AUTOSAR XML (schema 3.1.2)
package /Components/SWC_PFilSlow
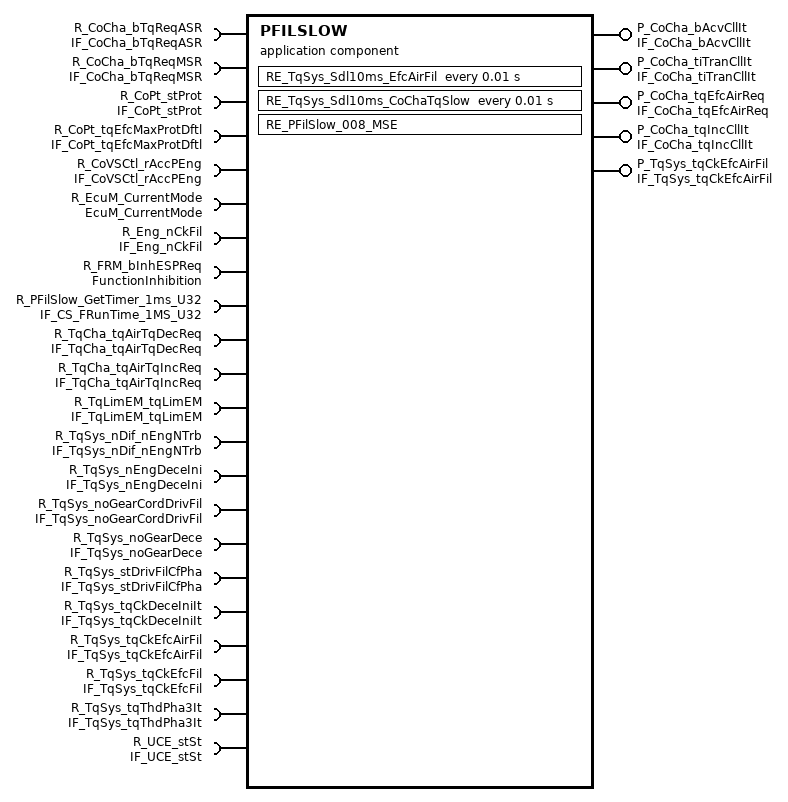
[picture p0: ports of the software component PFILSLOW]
  application software component type PFILSLOW  # PFilSlow
    5 x provide port:
      P_CoCha_bAcvCllIt: unqueued-sender-com-spec{data-element=CoCha_bAcvCllIt, can-invalidate=false, init-value=ConstantValue}, provided-interface=IF_CoCha_bAcvCllIt  # Requirement: 01552_10_01786-PFilSlow.I101(0)
      P_CoCha_tiTranCllIt: unqueued-sender-com-spec{data-element=CoCha_tiTranCllIt, can-invalidate=false, init-value=ConstantValue1}, provided-interface=IF_CoCha_tiTranCllIt  # Requirement: 01552_10_01786-PFilSlow.I102(0)
      P_CoCha_tqEfcAirReq: unqueued-sender-com-spec{data-element=CoCha_tqEfcAirReq, can-invalidate=false, init-value=ConstantValue3}, provided-interface=IF_CoCha_tqEfcAirReq  # Requirement: 01552_10_01786-PFilSlow.I100(0)
      P_CoCha_tqIncCllIt: unqueued-sender-com-spec{data-element=CoCha_tqIncCllIt, can-invalidate=false, init-value=ConstantValue5}, provided-interface=IF_CoCha_tqIncCllIt  # Requirement: 01552_10_01786-PFilSlow.I103(0)
      P_TqSys_tqCkEfcAirFil: unqueued-sender-com-spec{data-element=TqSys_tqCkEfcAirFil, can-invalidate=false, init-value=ConstantValue7}, provided-interface=IF_TqSys_tqCkEfcAirFil  # Requirement: 01552_10_01786-PFilSlow.I110(0)
    22 x require port:
      R_CoCha_bTqReqASR: unqueued-receiver-com-spec{data-element=CoCha_bTqReqASR, init-value=ConstantValue9, resync-time=0}, required-interface=IF_CoCha_bTqReqASR  # Requirement: 01552_10_01786-PFilSlow.I104(0)
      R_CoCha_bTqReqMSR: unqueued-receiver-com-spec{data-element=CoCha_bTqReqMSR, init-value=ConstantValue11, resync-time=0}, required-interface=IF_CoCha_bTqReqMSR  # Requirement: 01552_10_01786-PFilSlow.I105(0)
      R_CoPt_stProt: unqueued-receiver-com-spec{data-element=CoPt_stProt, init-value=ConstantValue13, resync-time=0}, required-interface=IF_CoPt_stProt  # Requirement: 01552_10_01786-PFilSlow.I123(0)
      R_CoPt_tqEfcMaxProtDftl: unqueued-receiver-com-spec{data-element=CoPt_tqEfcMaxProtDftl, init-value=ConstantValue15, resync-time=0}, required-interface=IF_CoPt_tqEfcMaxProtDftl  # Requirement: 01552_10_01786-PFilSlow.I124(0)
      R_CoVSCtl_rAccPEng: unqueued-receiver-com-spec{data-element=CoVSCtl_rAccPEng, init-value=ConstantValue17, resync-time=0}, required-interface=IF_CoVSCtl_rAccPEng  # Requirement: 01552_10_01786-PFilSlow.I112(0)
      R_EcuM_CurrentMode: required-interface=EcuM_CurrentMode  # Requirement: 01552_09_00532-SSTG-C007(0)
      R_Eng_nCkFil: unqueued-receiver-com-spec{data-element=Eng_nCkFil, init-value=ConstantValue19, resync-time=0}, required-interface=IF_Eng_nCkFil  # Requirement: 01552_10_01786-PFilSlow.I113(0)
      R_FRM_bInhESPReq: required-interface=FunctionInhibition  # Requirement: 01552_10_01786-PFilSlow.I700(0)
      R_PFilSlow_GetTimer_1ms_U32: required-interface=IF_CS_FRunTime_1MS_U32
      R_TqCha_tqAirTqDecReq: unqueued-receiver-com-spec{data-element=TqCha_tqAirTqDecReq, init-value=ConstantValue21, resync-time=0}, required-interface=IF_TqCha_tqAirTqDecReq  # Requirement: 01552_10_01786-PFilSlow.I106(0)
      R_TqCha_tqAirTqIncReq: unqueued-receiver-com-spec{data-element=TqCha_tqAirTqIncReq, init-value=ConstantValue23, resync-time=0}, required-interface=IF_TqCha_tqAirTqIncReq  # Requirement: 01552_10_01786-PFilSlow.I107(0)
      R_TqLimEM_tqLimEM: unqueued-receiver-com-spec{data-element=TqLimEM_tqLimEM, init-value=ConstantValue25, resync-time=0}, required-interface=IF_TqLimEM_tqLimEM  # Requirement: 01552_10_01786-PFilSlow.I114(0)
      R_TqSys_nDif_nEngNTrb: unqueued-receiver-com-spec{data-element=TqSys_nDif_nEngNTrb, init-value=ConstantValue27, resync-time=0}, required-interface=IF_TqSys_nDif_nEngNTrb  # Requirement: 01552_10_01786-PFilSlow.I115(0)
      R_TqSys_nEngDeceIni: unqueued-receiver-com-spec{data-element=TqSys_nEngDeceIni, init-value=ConstantValue29, resync-time=0}, required-interface=IF_TqSys_nEngDeceIni  # Requirement: 01552_10_01786-PFilSlow.I111(0)
      R_TqSys_noGearCordDrivFil: unqueued-receiver-com-spec{data-element=TqSys_noGearCordDrivFil, init-value=ConstantValue31, resync-time=0}, required-interface=IF_TqSys_noGearCordDrivFil  # Requirement: 01552_10_01786-PFilSlow.I116(0)
      R_TqSys_noGearDece: unqueued-receiver-com-spec{data-element=TqSys_noGearDece, init-value=ConstantValue33, resync-time=0}, required-interface=IF_TqSys_noGearDece  # Requirement: 01552_10_01786-PFilSlow.I117(0)
      R_TqSys_stDrivFilCfPha: unqueued-receiver-com-spec{data-element=TqSys_stDrivFilCfPha, init-value=ConstantValue35, resync-time=0}, required-interface=IF_TqSys_stDrivFilCfPha  # Requirement: 01552_10_01786-PFilSlow.I119(0)
      R_TqSys_tqCkDeceIniIt: unqueued-receiver-com-spec{data-element=TqSys_tqCkDeceIniIt, init-value=ConstantValue37, resync-time=0}, required-interface=IF_TqSys_tqCkDeceIniIt  # Requirement: 01552_10_01786-PFilSlow.I120(0)
      R_TqSys_tqCkEfcAirFil: unqueued-receiver-com-spec{data-element=TqSys_tqCkEfcAirFil, init-value=ConstantValue39, resync-time=0}, required-interface=IF_TqSys_tqCkEfcAirFil  # Requirement: 01552_10_01786-PFilSlow.I109(0)
      R_TqSys_tqCkEfcFil: unqueued-receiver-com-spec{data-element=TqSys_tqCkEfcFil, init-value=ConstantValue41, resync-time=0}, required-interface=IF_TqSys_tqCkEfcFil  # Requirement: 01552_10_01786-PFilSlow.I121(0)
      R_TqSys_tqThdPha3It: unqueued-receiver-com-spec{data-element=TqSys_tqThdPha3It, init-value=ConstantValue43, resync-time=0}, required-interface=IF_TqSys_tqThdPha3It  # Requirement: 01552_10_01786-PFilSlow.I122(0)
      R_UCE_stSt: required-interface=IF_UCE_stSt  # Requirement: 01552_09_00532-SSTG-C011(0)
  23 x constant specification:
    ConstantValue
      value:
        boolean literal ConstantValue: type=DT_CoCha_bAcvCllIt, value=false
    ConstantValue1
      value:
        integer literal ConstantValue1: type=DT_CoCha_tiTranCllIt, value=0
    ConstantValue11
      value:
        boolean literal ConstantValue11: type=DT_CoCha_bTqReqMSR, value=false
    ConstantValue13
      value:
        integer literal ConstantValue13: type=DT_CoPt_stProt, value=0
    ConstantValue15
      value:
        integer literal ConstantValue15: type=DT_CoPt_tqEfcMaxProtDftl, value=32000
    ConstantValue17
      value:
        integer literal ConstantValue17: type=DT_CoVSCtl_rAccPEng, value=0
    ConstantValue19
      value:
        integer literal ConstantValue19: type=DT_Eng_nCkFil, value=0
    ConstantValue21
      value:
        integer literal ConstantValue21: type=DT_TqCha_tqAirTqDecReq, value=0
    ConstantValue23
      value:
        integer literal ConstantValue23: type=DT_TqCha_tqAirTqIncReq, value=0
    ConstantValue25
      value:
        integer literal ConstantValue25: type=DT_TqLimEM_tqLimEM, value=0
    ConstantValue27
      value:
        integer literal ConstantValue27: type=DT_TqSys_nDif_nEngNTrb, value=0
    ConstantValue29
      value:
        integer literal ConstantValue29: type=DT_TqSys_nEngDeceIni, value=0
    ConstantValue3
      value:
        integer literal ConstantValue3: type=DT_CoCha_tqEfcAirReq, value=0
    ConstantValue31
      value:
        integer literal ConstantValue31: type=DT_TqSys_noGearCordDrivFil, value=0
    ConstantValue33
      value:
        integer literal ConstantValue33: type=DT_TqSys_noGearDece, value=0
    ConstantValue35
      value:
        integer literal ConstantValue35: type=DT_TqSys_stDrivFilCfPha, value=0
    ConstantValue37
      value:
        integer literal ConstantValue37: type=DT_TqSys_tqCkDeceIniIt, value=0
    ConstantValue39
      value:
        integer literal ConstantValue39: type=DT_TqSys_tqCkEfcAirFil, value=0
    ConstantValue41
      value:
        integer literal ConstantValue41: type=DT_TqSys_tqCkEfcFil, value=0
    ConstantValue43
      value:
        integer literal ConstantValue43: type=DT_TqSys_tqThdPha3It, value=0
    ConstantValue5
      value:
        integer literal ConstantValue5: type=DT_CoCha_tqIncCllIt, value=0
    ConstantValue7
      value:
        integer literal ConstantValue7: type=DT_TqSys_tqCkEfcAirFil, value=0
    ConstantValue9
      value:
        boolean literal ConstantValue9: type=DT_CoCha_bTqReqASR, value=false
  internal behavior IB_PFilSlow: component=PFILSLOW
    timing event EV_TqSys_Sdl10ms_EfcAirFil: mode-dependency=dependent-on-mode=[R_UCE_stSt.RCD_Mode.COM_LATCH, R_UCE_stSt.RCD_Mode.INTERNAL_PARTIAL_WAKEUP, R_UCE_stSt.RCD_Mode.INTERNAL_PARTIAL_WAKEUP_APC, R_UCE_stSt.RCD_Mode.PARTIAL_WAKEUP, R_UCE_stSt.RCD_Mode.SHUTDOWN_PREPARATION, R_UCE_stSt.RCD_Mode.SHUTDOWN_PREPARATION_APC, R_UCE_stSt.RCD_Mode.TRANSITORY], start-on-event=RE_TqSys_Sdl10ms_EfcAirFil, period=0.01
    timing event EV_TqSys_Sdl10ms_CoChaTqSlow: mode-dependency=dependent-on-mode=[R_UCE_stSt.RCD_Mode.COM_LATCH, R_UCE_stSt.RCD_Mode.INTERNAL_PARTIAL_WAKEUP, R_UCE_stSt.RCD_Mode.INTERNAL_PARTIAL_WAKEUP_APC, R_UCE_stSt.RCD_Mode.PARTIAL_WAKEUP, R_UCE_stSt.RCD_Mode.SHUTDOWN_PREPARATION, R_UCE_stSt.RCD_Mode.SHUTDOWN_PREPARATION_APC, R_UCE_stSt.RCD_Mode.TRANSITORY], start-on-event=RE_TqSys_Sdl10ms_CoChaTqSlow, period=0.01
    mode switch event EV_PFilSlow_008_MSE: start-on-event=RE_PFilSlow_008_MSE, activation=ENTRY, mode=R_EcuM_CurrentMode.currentMode.RUN
    runnable RE_TqSys_Sdl10ms_CoChaTqSlow
      7 x data receive point:
        dr_CoPt_stProt: data-element=R_CoPt_stProt.CoPt_stProt
        dr_TqSys_tqCkEfcAirFil: data-element=R_TqSys_tqCkEfcAirFil.TqSys_tqCkEfcAirFil
        dr_CoCha_bTqReqMSR: data-element=R_CoCha_bTqReqMSR.CoCha_bTqReqMSR
        dr_TqCha_tqAirTqDecReq: data-element=R_TqCha_tqAirTqDecReq.TqCha_tqAirTqDecReq
        dr_CoPt_tqEfcMaxProtDftl: data-element=R_CoPt_tqEfcMaxProtDftl.CoPt_tqEfcMaxProtDftl
        dr_CoCha_bTqReqASR: data-element=R_CoCha_bTqReqASR.CoCha_bTqReqASR
        dr_TqCha_tqAirTqIncReq: data-element=R_TqCha_tqAirTqIncReq.TqCha_tqAirTqIncReq
      4 x data send point:
        ds_CoCha_tqEfcAirReq: data-element=P_CoCha_tqEfcAirReq.CoCha_tqEfcAirReq
        ds_CoCha_tqIncCllIt: data-element=P_CoCha_tqIncCllIt.CoCha_tqIncCllIt
        ds_CoCha_bAcvCllIt: data-element=P_CoCha_bAcvCllIt.CoCha_bAcvCllIt
        ds_CoCha_tiTranCllIt: data-element=P_CoCha_tiTranCllIt.CoCha_tiTranCllIt
      sync call ssp_FRM_bInhESPReq: operation=R_FRM_bInhESPReq.GetFunctionPermission
      sync call ssp_GetTimer_1ms_U32: operation=R_PFilSlow_GetTimer_1ms_U32.GetTimer_1ms_U32
    runnable RE_TqSys_Sdl10ms_EfcAirFil
      11 x data receive point:
        dr_TqSys_nDif_nEngNTrb: data-element=R_TqSys_nDif_nEngNTrb.TqSys_nDif_nEngNTrb
        dr_Eng_nCkFil: data-element=R_Eng_nCkFil.Eng_nCkFil
        dr_TqSys_noGearDece: data-element=R_TqSys_noGearDece.TqSys_noGearDece
        dr_TqSys_noGearCordDrivFil: data-element=R_TqSys_noGearCordDrivFil.TqSys_noGearCordDrivFil
        dr_TqSys_tqThdPha3It: data-element=R_TqSys_tqThdPha3It.TqSys_tqThdPha3It
        dr_TqLimEM_tqLimEM: data-element=R_TqLimEM_tqLimEM.TqLimEM_tqLimEM
        dr_TqSys_tqCkEfcFil: data-element=R_TqSys_tqCkEfcFil.TqSys_tqCkEfcFil
        dr_CoVSCtl_rAccPEng: data-element=R_CoVSCtl_rAccPEng.CoVSCtl_rAccPEng
        dr_TqSys_stDrivFilCfPha: data-element=R_TqSys_stDrivFilCfPha.TqSys_stDrivFilCfPha
        dr_TqSys_nEngDeceIni: data-element=R_TqSys_nEngDeceIni.TqSys_nEngDeceIni
        dr_TqSys_tqCkDeceIniIt: data-element=R_TqSys_tqCkDeceIniIt.TqSys_tqCkDeceIniIt
      data send point ds_TqSys_tqCkEfcAirFil: data-element=P_TqSys_tqCkEfcAirFil.TqSys_tqCkEfcAirFil
      sync call ssp_GetTimer_1ms_U32: operation=R_PFilSlow_GetTimer_1ms_U32.GetTimer_1ms_U32
    runnable RE_PFilSlow_008_MSE  # RE_072713_10ms_init
      5 x data send point:
        ds_TqSys_tqCkEfcAirFil: data-element=P_TqSys_tqCkEfcAirFil.TqSys_tqCkEfcAirFil
        ds_CoCha_tiTranCllIt: data-element=P_CoCha_tiTranCllIt.CoCha_tiTranCllIt
        ds_CoCha_tqEfcAirReq: data-element=P_CoCha_tqEfcAirReq.CoCha_tqEfcAirReq
        ds_CoCha_tqIncCllIt: data-element=P_CoCha_tqIncCllIt.CoCha_tqIncCllIt
        ds_CoCha_bAcvCllIt: data-element=P_CoCha_bAcvCllIt.CoCha_bAcvCllIt
      sync call ssp_GetTimer_1ms_U32: operation=R_PFilSlow_GetTimer_1ms_U32.GetTimer_1ms_U32
  swc implementation Imp_PFilSlow: programming-language=C, behavior=IB_PFilSlow
    code-descriptors:
      code CodeDescriptor: type=SRC
        5 x xfile:
          PFILSLOW_Coord_Slow_Esp_c: url=PFILSLOW_Coord_Slow_Esp.c
          PFilSlow_MemMap_h: url=PFilSlow_MemMap.h
          PFilSlow_h: url=PFilSlow.h
          PFILSLOW_Prev_Agr_Slow_c: url=PFILSLOW_Prev_Agr_Slow.c
          PFilSlow_c: url=PFilSlow.c
